# UART register map
Vendor: Texas Instruments
Peripheral module from a debugger description file (folder ucd3138128A).
Registers are 32-bit, access not given, no defined reset value unless marked. A register's access mark holds for its fields unless they carry their own. Offsets are as the file gives them; lines under a group give offsets from that group; [hi:lo] are bit positions; {n}, {i} and the like mark numbered series; 'fields as' and 'values as' point back to an identical list; <NAME> marks a mode.

## UART
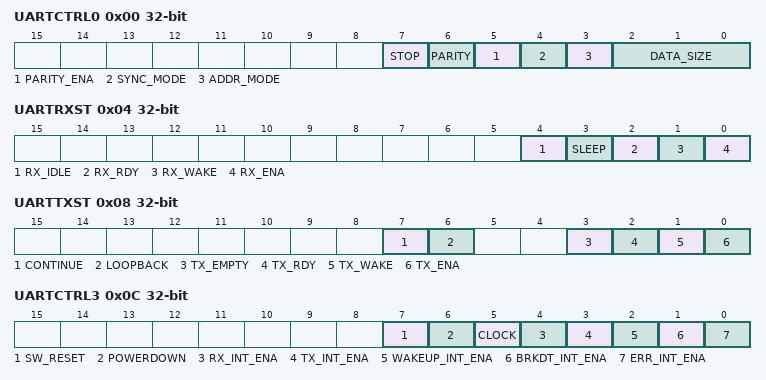
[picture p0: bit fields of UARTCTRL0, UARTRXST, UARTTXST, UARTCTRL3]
0x00 UARTCTRL0 — UART Control Register 0
  [7] STOP rw — Prescaler for clock
  [6] PARITY rw — Parity selection
  [5] PARITY_ENA rw — Parity enable
  [4] SYNC_MODE rw — Sync mode selection
  [3] ADDR_MODE rw — Address mode selection
  [2:0] DATA_SIZE rw — TX and RX data size
0x04 UARTRXST — UART Receive Status Register
  [4] RX_IDLE ro — RX idle status
  [3] SLEEP rw
  [2] RX_RDY ro — RX ready status
  [1] RX_WAKE ro — RX wake status
  [0] RX_ENA rw — RX enable
0x08 UARTTXST — UART Transmit Status Register
  [7] CONTINUE rw
  [6] LOOPBACK rw — Loopback enable
  [3] TX_EMPTY ro
  [2] TX_RDY ro — TX ready status
  [1] TX_WAKE rw — TX wake status
  [0] TX_ENA rw — TX enable
0x0C UARTCTRL3 — UART Control Register 3
  [7] SW_RESET rw — Software reset
  [6] POWERDOWN rw
  [5] CLOCK rw — Clock select
  [4] RX_INT_ENA rw — RX interrupt enable
  [3] TX_INT_ENA rw — TX interrupt enable
  [2] WAKEUP_INT_ENA rw — Wakeup interrupt enable
  [1] BRKDT_INT_ENA rw — Break detect interrupt enable
  [0] ERR_INT_ENA rw — RX error interrupt enable
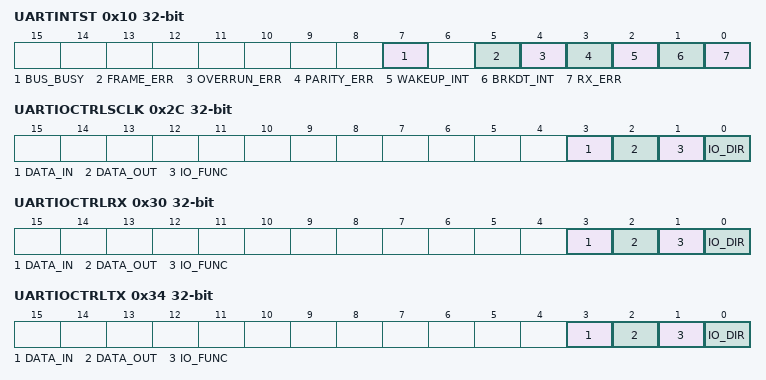
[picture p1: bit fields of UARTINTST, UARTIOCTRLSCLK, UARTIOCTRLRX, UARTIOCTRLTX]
0x10 UARTINTST — UART Interrupt Status Register
  [7] BUS_BUSY ro — RX bus busy flag
  [5] FRAME_ERR ro — RX framing error flag
  [4] OVERRUN_ERR ro — RX overrun error flag
  [3] PARITY_ERR ro — RX parity error flag
  [2] WAKEUP_INT ro — Wakeup interrupt flag
  [1] BRKDT_INT ro — Break detect interrupt flag
  [0] RX_ERR ro — RX error flag
0x14 UARTHBAUD — UART Baud Divisor High Byte Register
  [7:0] BAUD_DIV_H rw — High byte of baud divisor
0x18 UARTMBAUD — UART Baud Divisor Middle Byte Register
  [7:0] BAUD_DIV_M rw — Middle byte of baud divisor
0x1C UARTLBAUD — UART Baud Divisor Low Byte Register
  [7:0] BAUD_DIV_L rw — Low byte of baud divisor
0x24 UARTRXBUF — UART Receive Buffer
  [7:0] RXDAT ro — Receive data
0x28 UARTTXBUF — UART Transmit Buffer
  [7:0] TXDAT rw — Transmit data
0x2C UARTIOCTRLSCLK — UART SCLK Pin Control Register
  [3] DATA_IN ro — Input data from pin
  [2] DATA_OUT rw — Output data to pin
  [1] IO_FUNC rw — Pin function
  [0] IO_DIR rw — Pin direction
0x30 UARTIOCTRLRX — UART RX Pin Control Register
  fields as UARTIOCTRLSCLK
0x34 UARTIOCTRLTX — UART TX Pin Control Register
  fields as UARTIOCTRLSCLK
0x38 UARTSBAUD — UART TX BAUD Sub Bits
  [2:0] BAUD_SUB rw — TX Sub Bits
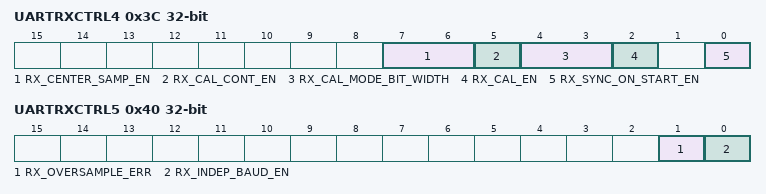
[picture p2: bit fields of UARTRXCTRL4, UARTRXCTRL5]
0x3C UARTRXCTRL4 — UART New Features Control Register
  [7:6] RX_CENTER_SAMP_EN rw — RX Center Sample EN
  [5] RX_CAL_CONT_EN rw — RX Continuous Cal Mode EN
  [4:3] RX_CAL_MODE_BIT_WIDTH rw
  [2] RX_CAL_EN rw — RX Cal Mode EN
  [0] RX_SYNC_ON_START_EN rw — RX Sync on Start Mode EN
0x40 UARTRXCTRL5 — UART Indep Baud Count EN Register
  [1] RX_OVERSAMPLE_ERR ro, [0] RX_INDEP_BAUD_EN rw
0x44 UARTRXMBAUD — UART RX Cal Mode Capture/Independent Baud Middle Byte
  [7:0] RX_M_BAUD rw — RX Middle Baud Byte
0x48 UARTRXLBAUD — UART RX Cal Mode Capture/Independent Baud Low Byte
  [7:0] RX_L_BAUD rw — RX Low Baud Byte
0x4C UARTRXSBAUD — UART RX Cal Mode Capture/Independent Baud Sub Bits
  [2:0] RX_S_BAUD rw — RX Sub Bits
